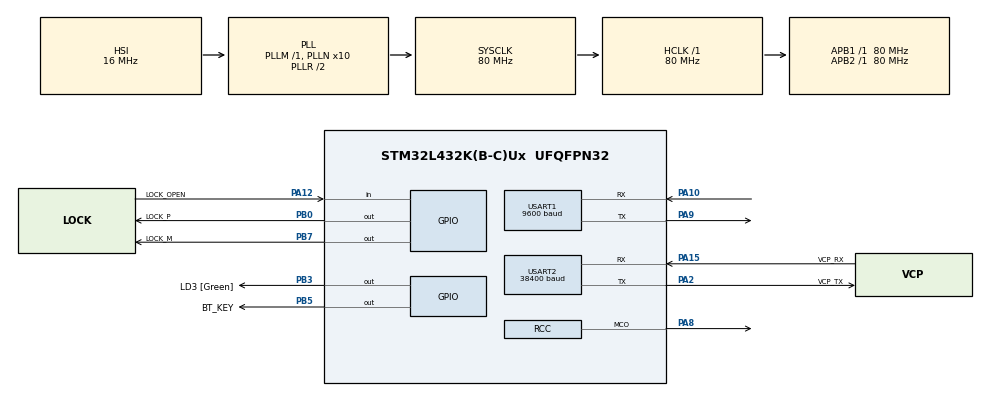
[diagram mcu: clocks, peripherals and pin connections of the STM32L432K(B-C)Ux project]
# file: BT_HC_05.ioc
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Mcu.Family=STM32L4
Mcu.Name=STM32L432K(B-C)Ux
Mcu.Package=UFQFPN32
NVIC.PriorityGroup=NVIC_PRIORITYGROUP_4
NVIC.USART1_IRQn=true\:0\:0\:false\:false\:true
NVIC.USART2_IRQn=true\:0\:0\:false\:false\:true
PA0-CK_IN.GPIO_Label=MCO [High speed clock in]
PA0-CK_IN.Signal=RCC_CK_IN
PA10.GPIO_Speed=GPIO_SPEED_FREQ_MEDIUM
PA10.Mode=Asynchronous
PA10.Signal=USART1_RX
PA12.GPIO_Label=LOCK_OPEN
PA12.GPIO_PuPd=GPIO_PULLUP
PA12.Signal=GPIO_Input
PA13\ (JTMS-SWDIO).GPIO_Label=SWDIO
PA13\ (JTMS-SWDIO).Mode=Serial_Wire
PA13\ (JTMS-SWDIO).Signal=SYS_JTMS-SWDIO
PA14\ (JTCK-SWCLK).GPIO_Label=SWCLK
PA14\ (JTCK-SWCLK).Mode=Serial_Wire
PA14\ (JTCK-SWCLK).Signal=SYS_JTCK-SWCLK
PA15\ (JTDI).GPIO_Label=VCP_RX
PA15\ (JTDI).GPIO_Speed=GPIO_SPEED_FREQ_HIGH
PA15\ (JTDI).Mode=Asynchronous
PA15\ (JTDI).Signal=USART2_RX
PA2.GPIO_Label=VCP_TX
PA2.GPIO_Speed=GPIO_SPEED_FREQ_HIGH
PA2.Mode=Asynchronous
PA2.Signal=USART2_TX
PA8.Mode=Clock-out
PA8.Signal=RCC_MCO
PA9.GPIO_Speed=GPIO_SPEED_FREQ_MEDIUM
PA9.Mode=Asynchronous
PA9.Signal=USART1_TX
PB0.GPIO_Label=LOCK_P
PB0.Signal=GPIO_Output
PB3\ (JTDO-TRACESWO).GPIO_Label=LD3 [Green]
PB3\ (JTDO-TRACESWO).GPIO_PuPd=GPIO_PULLUP
PB3\ (JTDO-TRACESWO).Signal=GPIO_Output
PB5.GPIO_Label=BT_KEY
PB5.Signal=GPIO_Output
PB7.GPIO_Label=LOCK_M
PB7.Signal=GPIO_Output
PC14-OSC32_IN\ (PC14).Signal=RCC_OSC32_IN
PC15-OSC32_OUT\ (PC15).Signal=RCC_OSC32_OUT
ProjectManager.HeapSize=0x200
ProjectManager.StackSize=0x400
ProjectManager.TargetToolchain=Other Toolchains (GPDSC)
RCC.ADCFreq_Value=64000000
RCC.AHBFreq_Value=80000000
RCC.APB1Freq_Value=80000000
RCC.APB1TimFreq_Value=80000000
RCC.APB2Freq_Value=80000000
RCC.APB2TimFreq_Value=80000000
RCC.CortexFreq_Value=80000000
RCC.HCLKFreq_Value=80000000
RCC.HSE_VALUE=8000000
RCC.HSI16_VALUE=16000000
RCC.HSI48_VALUE=48000000
RCC.HSI_VALUE=16000000
RCC.LSE_VALUE=32768
RCC.MSI_VALUE=4000000
RCC.PLLMUL=RCC_PLLMUL_4
RCC.PLLN=10
RCC.PLLSourceVirtual=RCC_PLLSOURCE_HSI
RCC.SYSCLKFreq_VALUE=80000000
RCC.SYSCLKSource=RCC_SYSCLKSOURCE_PLLCLK
RCC.USBFreq_Value=64000000
RCC.VCOOutputFreq_Value=160000000
USART1.BaudRate=9600
USART1.WordLength=UART_WORDLENGTH_8B
USART2.BaudRate=38400
USART2.WordLength=UART_WORDLENGTH_8B
board=NUCLEO-L432KC

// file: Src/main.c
/**
  ******************************************************************************
  * File Name          : main.c
  * Description        : Main program body
  ******************************************************************************
  *
  * COPYRIGHT(c) 2017 STMicroelectronics
  *
  * Redistribution and use in source and binary forms, with or without modification,
  * are permitted provided that the following conditions are met:
  *   1. Redistributions of source code must retain the above copyright notice,
  *      this list of conditions and the following disclaimer.
  *   2. Redistributions in binary form must reproduce the above copyright notice,
  *      this list of conditions and the following disclaimer in the documentation
  *      and/or other materials provided with the distribution.
  *   3. Neither the name of STMicroelectronics nor the names of its contributors
  *      may be used to endorse or promote products derived from this software
  *      without specific prior written permission.
  *
  * THIS SOFTWARE IS PROVIDED BY THE COPYRIGHT HOLDERS AND CONTRIBUTORS "AS IS"
  * AND ANY EXPRESS OR IMPLIED WARRANTIES, INCLUDING, BUT NOT LIMITED TO, THE
  * IMPLIED WARRANTIES OF MERCHANTABILITY AND FITNESS FOR A PARTICULAR PURPOSE ARE
  * DISCLAIMED. IN NO EVENT SHALL THE COPYRIGHT HOLDER OR CONTRIBUTORS BE LIABLE
  * FOR ANY DIRECT, INDIRECT, INCIDENTAL, SPECIAL, EXEMPLARY, OR CONSEQUENTIAL
  * DAMAGES (INCLUDING, BUT NOT LIMITED TO, PROCUREMENT OF SUBSTITUTE GOODS OR
  * SERVICES; LOSS OF USE, DATA, OR PROFITS; OR BUSINESS INTERRUPTION) HOWEVER
  * CAUSED AND ON ANY THEORY OF LIABILITY, WHETHER IN CONTRACT, STRICT LIABILITY,
  * OR TORT (INCLUDING NEGLIGENCE OR OTHERWISE) ARISING IN ANY WAY OUT OF THE USE
  * OF THIS SOFTWARE, EVEN IF ADVISED OF THE POSSIBILITY OF SUCH DAMAGE.
  *
  ******************************************************************************
  */
#include "main.h"
#include "stm32l4xx_hal.h"
#include "usart.h"
#include "gpio.h"

/* USER CODE BEGIN Includes */
#include <stdbool.h>
#include "LockApp.h"
/* USER CODE END Includes */

/* USER CODE BEGIN PV */
/* Private variables ---------------------------------------------------------*/

/* USER CODE END PV */

void SystemClock_Config(void);
void Error_Handler(void);

/* USER CODE BEGIN PFP */
/* Private function prototypes -----------------------------------------------*/

/* USER CODE END PFP */

int main(void)
{

  /* MCU Configuration----------------------------------------------------------*/

  /* Reset of all peripherals, Initializes the Flash interface and the Systick. */
  HAL_Init();

  /* Configure the system clock */
  SystemClock_Config();

  /* Initialize all configured peripherals */
  MX_GPIO_Init();
  MX_USART1_UART_Init();
  MX_USART2_UART_Init();

  /* USER CODE BEGIN 2 */
	//LockApp();
  /* USER CODE END 2 */

  /* Infinite loop */
  /* USER CODE BEGIN WHILE */
	HAL_StatusTypeDef statusReceive;
	HAL_StatusTypeDef statusTransmit;
	HAL_Delay(1000);
	HAL_GPIO_WritePin(BT_KEY_GPIO_Port, BT_KEY_Pin, GPIO_PIN_SET); // set to 1 so we can use commands
	unsigned char szBuffer[] = "Lock ready !\r\n";
// huart1 goes to bluetooth
//	statusTransmit = HAL_UART_Transmit(&huart1, &szBuffer[0], 14, 1000);
// huart2 is for debug on the stlink
	statusTransmit = HAL_UART_Transmit(&huart2, &szBuffer[0], 14, 1000);
  while (1)
  {
  /* USER CODE END WHILE */

  /* USER CODE BEGIN 3 */

	  LockApp();

  }
  /* USER CODE END 3 */

}

/** System Clock Configuration
*/
void SystemClock_Config(void)
{

  RCC_OscInitTypeDef RCC_OscInitStruct;
  RCC_ClkInitTypeDef RCC_ClkInitStruct;
  RCC_PeriphCLKInitTypeDef PeriphClkInit;

    /**Initializes the CPU, AHB and APB busses clocks
    */
  RCC_OscInitStruct.OscillatorType = RCC_OSCILLATORTYPE_HSI;
  RCC_OscInitStruct.HSIState = RCC_HSI_ON;
  RCC_OscInitStruct.HSICalibrationValue = 16;
  RCC_OscInitStruct.PLL.PLLState = RCC_PLL_ON;
  RCC_OscInitStruct.PLL.PLLSource = RCC_PLLSOURCE_HSI;
  RCC_OscInitStruct.PLL.PLLM = 1;
  RCC_OscInitStruct.PLL.PLLN = 10;
  RCC_OscInitStruct.PLL.PLLP = RCC_PLLP_DIV7;
  RCC_OscInitStruct.PLL.PLLQ = RCC_PLLQ_DIV2;
  RCC_OscInitStruct.PLL.PLLR = RCC_PLLR_DIV2;
  if (HAL_RCC_OscConfig(&RCC_OscInitStruct) != HAL_OK)
  {
    Error_Handler();
  }

    /**Initializes the CPU, AHB and APB busses clocks
    */
  RCC_ClkInitStruct.ClockType = RCC_CLOCKTYPE_HCLK|RCC_CLOCKTYPE_SYSCLK
                              |RCC_CLOCKTYPE_PCLK1|RCC_CLOCKTYPE_PCLK2;
  RCC_ClkInitStruct.SYSCLKSource = RCC_SYSCLKSOURCE_PLLCLK;
  RCC_ClkInitStruct.AHBCLKDivider = RCC_SYSCLK_DIV1;
  RCC_ClkInitStruct.APB1CLKDivider = RCC_HCLK_DIV1;
  RCC_ClkInitStruct.APB2CLKDivider = RCC_HCLK_DIV1;

  if (HAL_RCC_ClockConfig(&RCC_ClkInitStruct, FLASH_LATENCY_4) != HAL_OK)
  {
    Error_Handler();
  }

  PeriphClkInit.PeriphClockSelection = RCC_PERIPHCLK_USART1|RCC_PERIPHCLK_USART2;
  PeriphClkInit.Usart1ClockSelection = RCC_USART1CLKSOURCE_PCLK2;
  PeriphClkInit.Usart2ClockSelection = RCC_USART2CLKSOURCE_PCLK1;
  if (HAL_RCCEx_PeriphCLKConfig(&PeriphClkInit) != HAL_OK)
  {
    Error_Handler();
  }

  HAL_RCC_MCOConfig(RCC_MCO1, RCC_MCO1SOURCE_SYSCLK, RCC_MCODIV_1);

    /**Configure the main internal regulator output voltage
    */
  if (HAL_PWREx_ControlVoltageScaling(PWR_REGULATOR_VOLTAGE_SCALE1) != HAL_OK)
  {
    Error_Handler();
  }

    /**Configure the Systick interrupt time
    */
  HAL_SYSTICK_Config(HAL_RCC_GetHCLKFreq()/1000);

    /**Configure the Systick
    */
  HAL_SYSTICK_CLKSourceConfig(SYSTICK_CLKSOURCE_HCLK);

  /* SysTick_IRQn interrupt configuration */
  HAL_NVIC_SetPriority(SysTick_IRQn, 0, 0);
}

void Error_Handler(void)
{
  while(1)
  {
  }
}

/************************ (C) COPYRIGHT STMicroelectronics *****END OF FILE****/
